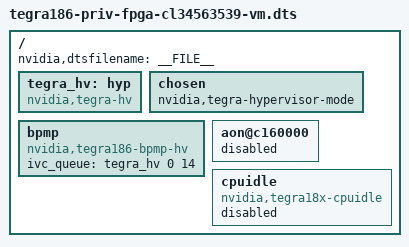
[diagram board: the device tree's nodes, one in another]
/*
 * arch/arm64/boot/dts/tegra186-fpga-cl34563539-vm.dts
 *
 * Copyright (c) 2015, NVIDIA CORPORATION.  All rights reserved.
 *
 * This program is free software; you can redistribute it and/or modify
 * it under the terms of the GNU General Public License as published by
 * the Free Software Foundation; version 2 of the License.
 *
 * This program is distributed in the hope that it will be useful, but WITHOUT
 * ANY WARRANTY; without even the implied warranty of MERCHANTABILITY or
 * FITNESS FOR A PARTICULAR PURPOSE.  See the GNU General Public License for
 * more details.
 *
 * You should have received a copy of the GNU General Public License along
 * with this program; if not, write to the Free Software Foundation, Inc.,
 * 51 Franklin Street, Fifth Floor, Boston, MA  02110-1301, USA.
 *
 */

#include "tegra186-priv-fpga-cl34563539.dts"

/ {
	nvidia,dtsfilename = __FILE__;

	tegra_hv: hyp {
		compatible = "nvidia,tegra-hv";
		status = "okay";
	};

	chosen {
		nvidia,tegra-hypervisor-mode;
	};

	bpmp {
		compatible = "nvidia,tegra186-bpmp-hv";
		ivc_queue = <&tegra_hv 0 14>;
	};

	aon@c160000 {
		status = "disabled";
	};

	cpuidle {
		compatible = "nvidia,tegra18x-cpuidle";
		status = "disabled";
	};


};
